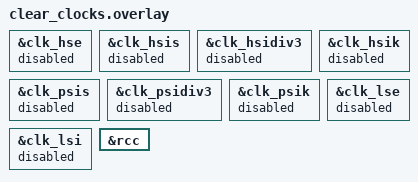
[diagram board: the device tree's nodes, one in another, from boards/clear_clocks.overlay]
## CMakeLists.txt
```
# SPDX-License-Identifier: Apache-2.0

cmake_minimum_required(VERSION 3.28.0)

find_package(Zephyr REQUIRED HINTS $ENV{ZEPHYR_BASE})
project(stm32_clock_configuration_c5)

FILE(GLOB app_sources src/*.c)
target_sources(app PRIVATE ${app_sources})
```

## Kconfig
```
# STM32C5 clock test configuration options

# Copyright (c) 2026 STMicroelectronics
# SPDX-License-Identifier: Apache-2.0

config CLOCK_CFG_USE_STM32_HAL_RCC
	bool "Use HAL RCC"
	default y
	select USE_STM32_HAL_RCC

source "Kconfig.zephyr"
```

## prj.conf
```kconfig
# SPDX-FileCopyrightText: Copyright The Zephyr Project Contributors
# SPDX-License-Identifier: Apache-2.0

CONFIG_ZTEST=y
CONFIG_CLOCK_CFG_USE_STM32_HAL_RCC=y
```

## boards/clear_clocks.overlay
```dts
/*
 * Copyright (c) 2026 STMicroelectronics
 *
 * SPDX-License-Identifier: Apache-2.0
 */

/*
 * Warning: This overlay clears clocks back to a state equivalent to what could
 * be found in stm32c5.dtsi
 */

&clk_hse {
	status = "disabled";
	/delete-property/ clock-frequency;
	/delete-property/ hse-bypass;
};

&clk_hsis {
	status = "disabled";
};

&clk_hsidiv3 {
	status = "disabled";
};

&clk_hsik {
	status = "disabled";
	/delete-property/ xsik-div;
};

&clk_psis {
	status = "disabled";
	/delete-property/ clock-frequency;
};

&clk_psidiv3 {
	status = "disabled";
	/delete-property/ clock-frequency;
};

&clk_psik {
	status = "disabled";
	/delete-property/ xsik-div;
	/delete-property/ clock-frequency;
};

&clk_lse {
	status = "disabled";
};

&clk_lsi {
	status = "disabled";
};

&rcc {
	/delete-property/ clocks;
	/delete-property/ clock-frequency;
	/delete-property/ ahb-prescaler;
	/delete-property/ apb1-prescaler;
	/delete-property/ apb2-prescaler;
	/delete-property/ apb4-prescaler;
	/delete-property/ st,psi-source;
	/delete-property/ st,psi-frequency;
};
```

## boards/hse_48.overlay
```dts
/*
 * Copyright (c) 2026 STMicroelectronics
 *
 * SPDX-License-Identifier: Apache-2.0
 */

/*
 * Warning: This overlay performs configuration from clean sheet.
 * It is assumed that it is applied after clear_clocks.overlay file.
 */

&clk_hse {
	clock-frequency = <DT_FREQ_M(48)>;
	status = "okay";
};

&rcc {
	clocks = <&clk_hse>;
	clock-frequency = <DT_FREQ_M(48)>;
	ahb-prescaler = <1>;
	apb1-prescaler = <2>;
	apb2-prescaler = <2>;
	apb3-prescaler = <2>;
};
```

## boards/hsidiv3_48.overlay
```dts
/*
 * Copyright (c) 2026 STMicroelectronics
 *
 * SPDX-License-Identifier: Apache-2.0
 */

/*
 * Warning: This overlay performs configuration from clean sheet.
 * It is assumed that it is applied after clear_clocks.overlay file.
 */

&clk_hsidiv3 {
	clock-frequency = <DT_FREQ_M(48)>;
	status = "okay";
};

&rcc {
	clocks = <&clk_hsidiv3>;
	clock-frequency = <DT_FREQ_M(48)>;
	ahb-prescaler = <1>;
	apb1-prescaler = <2>;
	apb2-prescaler = <2>;
	apb3-prescaler = <2>;
};
```

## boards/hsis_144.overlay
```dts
/*
 * Copyright (c) 2026 STMicroelectronics
 *
 * SPDX-License-Identifier: Apache-2.0
 */

/*
 * Warning: This overlay performs configuration from clean sheet.
 * It is assumed that it is applied after clear_clocks.overlay file.
 */

&clk_hsis {
	clock-frequency = <DT_FREQ_M(144)>;
	status = "okay";
};

&rcc {
	clocks = <&clk_hsis>;
	clock-frequency = <DT_FREQ_M(144)>;
	ahb-prescaler = <1>;
	apb1-prescaler = <2>;
	apb2-prescaler = <2>;
	apb3-prescaler = <2>;
};
```

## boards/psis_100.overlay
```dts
/*
 * Copyright (c) 2026 STMicroelectronics
 *
 * SPDX-License-Identifier: Apache-2.0
 */

/*
 * Warning: This overlay performs configuration from clean sheet.
 * It is assumed that it is applied after clear_clocks.overlay file.
 */

&clk_hsis {
	clock-frequency = <DT_FREQ_M(144)>;
	status = "okay";
};

&clk_psis {
	clock-frequency = <DT_FREQ_M(100)>;
	status = "okay";
};

&rcc {
	clocks = <&clk_psis>;
	clock-frequency = <DT_FREQ_M(100)>;
	ahb-prescaler = <1>;
	apb1-prescaler = <2>;
	apb2-prescaler = <2>;
	apb3-prescaler = <2>;
	st,psi-frequency = <100>;
	st,psi-source = "HSIDIV18";
};
```

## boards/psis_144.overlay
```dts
/*
 * Copyright (c) 2026 STMicroelectronics
 *
 * SPDX-License-Identifier: Apache-2.0
 */

/*
 * Warning: This overlay performs configuration from clean sheet.
 * It is assumed that it is applied after clear_clocks.overlay file.
 */

&clk_hse {
	clock-frequency = <DT_FREQ_M(48)>;
	status = "okay";
};

&clk_psis {
	clock-frequency = <DT_FREQ_M(144)>;
	status = "okay";
};

&rcc {
	clocks = <&clk_psis>;
	clock-frequency = <DT_FREQ_M(144)>;
	ahb-prescaler = <1>;
	apb1-prescaler = <2>;
	apb2-prescaler = <2>;
	apb3-prescaler = <2>;
	st,psi-frequency = <144>;
	st,psi-source = "HSE";
};
```

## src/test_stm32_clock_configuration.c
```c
/*
 * Copyright (c) 2026 STMicroelectronics
 *
 * SPDX-License-Identifier: Apache-2.0
 */

#include <soc.h>
#include <zephyr/drivers/clock_control.h>
#include <zephyr/drivers/clock_control/stm32_clock_control.h>
#include <zephyr/logging/log.h>
#include <zephyr/ztest.h>

LOG_MODULE_REGISTER(test);

ZTEST(stm32c5_clock_core_config, test_sysclk_src)
{
	hal_rcc_sysclk_src_t sys_clk_src = HAL_RCC_GetSYSCLKSource();

#if IS_ENABLED(STM32_SYSCLK_SRC_HSIS)
	zassert_equal(HAL_RCC_SYSCLK_SRC_HSIS, sys_clk_src,
			"Expected sysclk src: HSIS (0x%x). Actual: 0x%x",
			(uint32_t)HAL_RCC_SYSCLK_SRC_HSIS, sys_clk_src);
#elif IS_ENABLED(STM32_SYSCLK_SRC_HSIDIV3)
	zassert_equal(HAL_RCC_SYSCLK_SRC_HSIDIV3, sys_clk_src,
			"Expected sysclk src: HSIDIV3 (0x%x). Actual: 0x%x",
			(uint32_t)HAL_RCC_SYSCLK_SRC_HSIDIV3, sys_clk_src);
#elif IS_ENABLED(STM32_SYSCLK_SRC_HSE)
	zassert_equal(HAL_RCC_SYSCLK_SRC_HSE, sys_clk_src,
			"Expected sysclk src: HSE (0x%x). Actual: 0x%x",
			(uint32_t)HAL_RCC_SYSCLK_SRC_HSE, sys_clk_src);
#elif IS_ENABLED(STM32_SYSCLK_SRC_PSIS)
	zassert_equal(HAL_RCC_SYSCLK_SRC_PSIS, sys_clk_src,
			"Expected sysclk src: PSIS (0x%x). Actual: 0x%x",
			(uint32_t)HAL_RCC_SYSCLK_SRC_PSIS, sys_clk_src);
#else
	/* Case not expected */
	zassert_true(IS_ENABLED(STM32_SYSCLK_SRC_HSIS) ||
		     IS_ENABLED(STM32_SYSCLK_SRC_HSIDIV3) ||
		     IS_ENABLED(STM32_SYSCLK_SRC_HSE) ||
		     IS_ENABLED(STM32_SYSCLK_SRC_PSIS),
		     "Not expected. sys_clk_src: %d\n", sys_clk_src);
#endif
}

ZTEST(stm32c5_clock_core_config, test_sysclk_freq)
{
	uint32_t sysclk_freq = HAL_RCC_GetSYSCLKFreq();

	zassert_equal(CONFIG_SYS_CLOCK_HW_CYCLES_PER_SEC, sysclk_freq,
		      "Expected sysclk_freq: %d. Actual sysclk_freq: %d",
		      CONFIG_SYS_CLOCK_HW_CYCLES_PER_SEC, sysclk_freq);
}

#if IS_ENABLED(STM32_HSE_ENABLED)
ZTEST(stm32c5_clock_core_config, test_hse_css)
{
	/* there is no function to read CSS status, so read directly from the SoC register */
	bool css_enabled = (STM32_READ_BIT(RCC->CR1, RCC_CR1_HSECSSON) == RCC_CR1_HSECSSON);

	if (IS_ENABLED(STM32_HSE_CSS)) {
		zassert_true(css_enabled, "HSE CSS is not enabled");
	} else {
		zassert_false(css_enabled, "HSE CSS unexpectedly enabled");
	}
}
#endif /* STM32_HSE_ENABLED */

#if IS_ENABLED(STM32_LSE_ENABLED)
ZTEST(stm32c5_clock_core_config, test_lse_css)
{
	bool css_enabled = (READ_BIT(RCC->RTCCR, RCC_RTCCR_LSECSSON) == 1U);

	if (IS_ENABLED(STM32_LSE_CSS)) {
		zassert_true(css_enabled, "LSE CSS is not enabled");
	} else {
		zassert_false(css_enabled, "LSE CSS unexpectedly enabled");
	}
}
#endif /* STM32_LSE_ENABLED */

ZTEST_SUITE(stm32c5_clock_core_config, NULL, NULL, NULL, NULL, NULL);
```
